# GD32H71x_72x register map
File version: 1.0
CPU: CM7 r1p2, little endian, MPU, FPU, 4 interrupt priority bits
Registers are 32-bit, read-write, reset 0x0 unless marked. A register's access mark holds for its fields unless they carry their own. Offsets are from the block's base; [hi:lo] are bit positions; {n}, {i} and the like mark numbered series; 'fields as' and 'values as' point back to an identical list.

## ADC0 — Analog-to-digital converter
Base 0x40012400
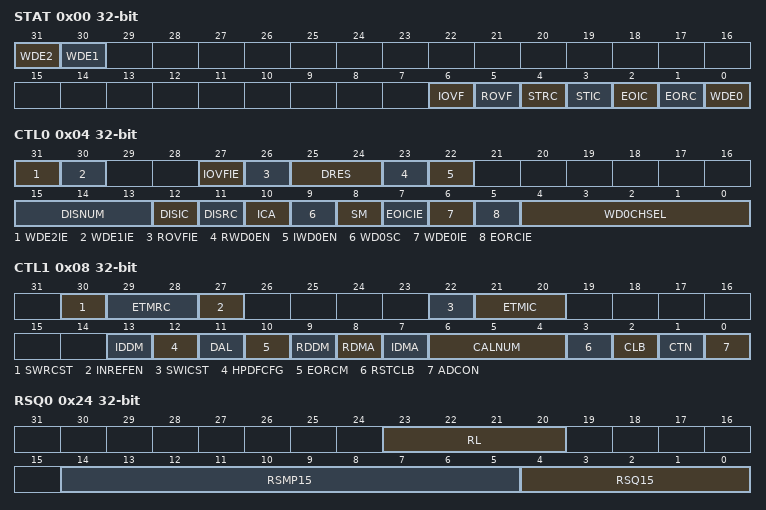
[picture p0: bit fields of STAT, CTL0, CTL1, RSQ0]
0x00 STAT — Status register
  [31] WDE2 — Analog watchdog 2 event flag
  [30] WDE1 — Analog watchdog 1 event flag
  [6] IOVF — Inserted data register overflow flag
  [5] ROVF — Routine data register overflow flag
  [4] STRC — Start flag of routine sequence
  [3] STIC — Start flag of inserted sequence
  [2] EOIC — End of inserted sequence conversion flag
  [1] EORC — End of routine sequence conversion flag
  [0] WDE0 — Analog watchdog 0 event flag
0x04 CTL0 — Control register 0
  [31] WDE2IE — Interrupt enable for WDE2
  [30] WDE1IE — Interrupt enable for WDE1
  [27] IOVFIE — Interrupt enable for IOVF
  [26] ROVFIE — Interrupt enable for ROVF
  [25:24] DRES — ADC data resolution for ADC0/ADC1
  [23] RWD0EN — Routine channel analog watchdog 0 enable
  [22] IWD0EN — Inserted channel analog watchdog 0 enable
  [15:13] DISNUM — Number of conversions in discontinuous mode
  [12] DISIC — Discontinuous mode on inserted channels
  [11] DISRC — Discontinuous mode on routine channels
  [10] ICA — Inserted sequence convert automatically
  [9] WD0SC — When in scan mode, analog watchdog 0 is effective on a single channel
  [8] SM — Scan mode
  [7] EOICIE — Interrupt enable for EOIC
  [6] WDE0IE — Interrupt enable for WDE0
  [5] EORCIE — Interrupt enable for EORC
  [4:0] WD0CHSEL — Analog watchdog 0 channel select
0x08 CTL1 — Control register 1
  [30] SWRCST — Software start on routine channel.
  [29:28] ETMRC — External trigger mode for routine channel
  [27] INREFEN — Internal reference enable
  [22] SWICST — Software start on inserted channel.
  [21:20] ETMIC — External trigger mode for inserted channel
  [13] IDDM — Inserted DMA disable mode
  [12] HPDFCFG — HPDF mode configuration
  [11] DAL — Data alignment
  [10] EORCM — End of routine sequence conversion mode
  [9] RDDM — Routine DMA disable mode
  [8] RDMA — Routine DMA request enable.
  [7] IDMA — Inserted DMA request enable.
  [6:4] CALNUM — Calibration Times
  [3] RSTCLB — Reset calibration
  [2] CLB — ADC calibration
  [1] CTN — Continuous mode
  [0] ADCON
{0xC+4i} IOFF{i} (i=0..3) — Inserted channel data offset registe {i}
  [21:0] IOFF — Data offset for inserted channel x
0x1C WDHT0 reset 0x3FFFFF — Watchdog high threshold register0
  [21:0] WDHT0 — High threshold for analog watchdog 0
0x20 WDLT0 — Watchdog low threshold register0
  [21:0] WDLT0 — Low threshold for analog watchdog 0
0x24 RSQ0 — Routine sequence register 0
  [23:20] RL — Routine channel length.
  [14:5] RSMP15 — Routine channel sample time
  [4:0] RSQ15 — refer to RSQ0[4:0] description
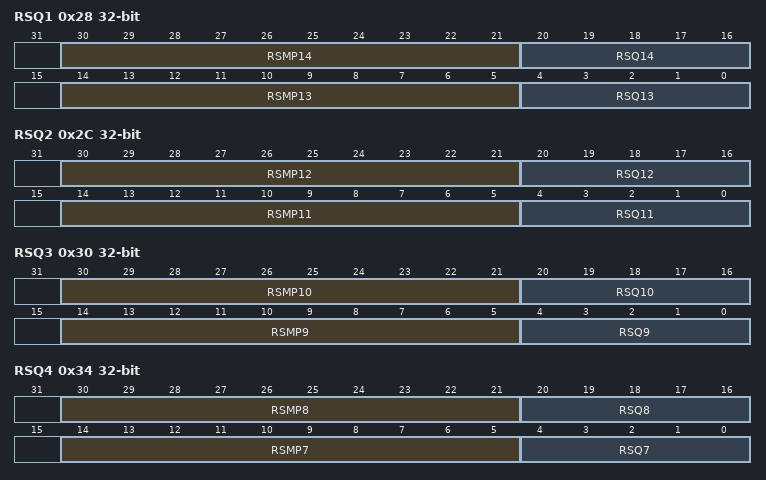
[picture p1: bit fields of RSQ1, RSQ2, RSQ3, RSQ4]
0x28 RSQ1 — Routine sequence register 1
  [30:21] RSMP14 — Routine channel sample time
  [20:16] RSQ14 — refer to RSQ0[4:0] description
  [14:5] RSMP13 — Routine channel sample time
  [4:0] RSQ13 — refer to RSQ0[4:0] description
0x2C RSQ2 — Routine sequence register 2
  [30:21] RSMP12 — Routine channel sample time
  [20:16] RSQ12 — refer to RSQ0[4:0] description
  [14:5] RSMP11 — Routine channel sample time
  [4:0] RSQ11 — refer to RSQ0[4:0] description
0x30 RSQ3 — Routine sequence register 3
  [30:21] RSMP10 — Routine channel sample time
  [20:16] RSQ10 — refer to RSQ0[4:0] description
  [14:5] RSMP9 — Routine channel sample time
  [4:0] RSQ9 — refer to RSQ0[4:0] description
0x34 RSQ4 — Routine sequence register 4
  [30:21] RSMP8 — Routine channel sample time
  [20:16] RSQ8 — refer to RSQ0[4:0] description
  [14:5] RSMP7 — Routine channel sample time
  [4:0] RSQ7 — refer to RSQ0[4:0] description
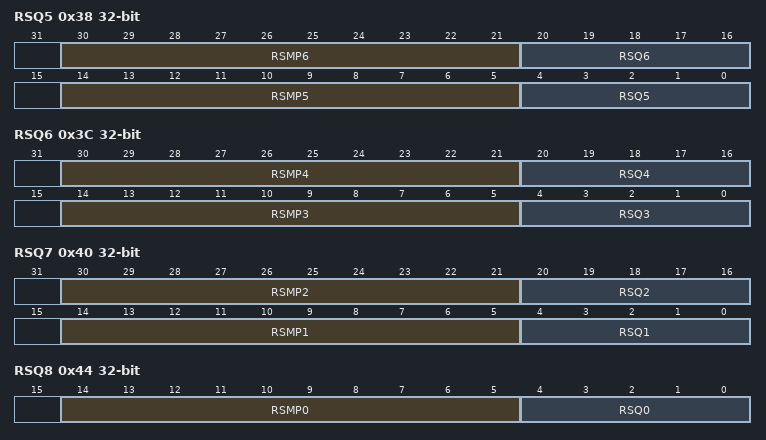
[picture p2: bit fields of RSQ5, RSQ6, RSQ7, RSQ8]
0x38 RSQ5 — Routine sequence register 5
  [30:21] RSMP6 — Routine channel sample time
  [20:16] RSQ6 — refer to RSQ0[4:0] description
  [14:5] RSMP5 — Routine channel sample time
  [4:0] RSQ5 — refer to RSQ0[4:0] description
0x3C RSQ6 — Routine sequence register 6
  [30:21] RSMP4 — Routine channel sample time
  [20:16] RSQ4 — refer to RSQ0[4:0] description
  [14:5] RSMP3 — Routine channel sample time
  [4:0] RSQ3 — refer to RSQ0[4:0] description
0x40 RSQ7 — Routine sequence register 7
  [30:21] RSMP2 — Routine channel sample time
  [20:16] RSQ2 — refer to RSQ0[4:0] description
  [14:5] RSMP1 — Routine channel sample time
  [4:0] RSQ1 — refer to RSQ0[4:0] description
0x44 RSQ8 — Routine sequence register 8
  [14:5] RSMP0 — Routine channel sample time
  [4:0] RSQ0 — The channel number (0
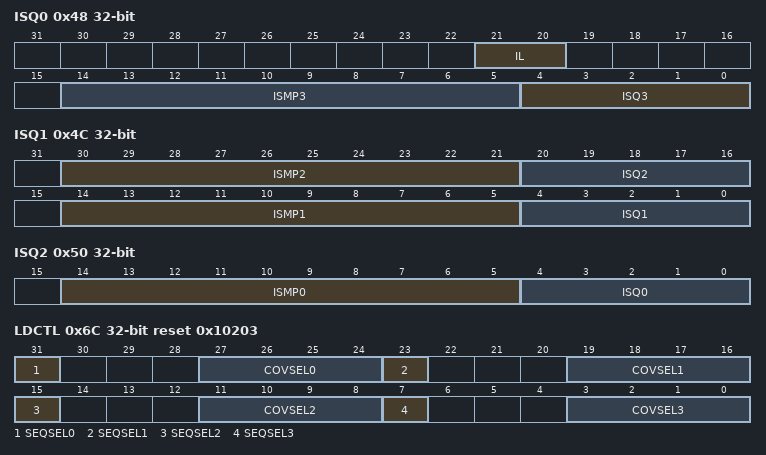
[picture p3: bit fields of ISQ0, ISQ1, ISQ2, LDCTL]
0x48 ISQ0 — Inserted sequence register 0
  [21:20] IL — Inserted sequence length.
  [14:5] ISMP3 — Inserted channel sample time
  [4:0] ISQ3 — refer to ISQ0[4:0] description
0x4C ISQ1 — Inserted sequence register 1
  [30:21] ISMP2 — Inserted channel sample time
  [20:16] ISQ2 — refer to ISQ0[4:0] description
  [14:5] ISMP1 — Inserted channel sample time
  [4:0] ISQ1 — refer to ISQ0[4:0] description.
0x50 ISQ2 — Inserted sequence register 2
  [14:5] ISMP0 — Inserted channel sample time
  [4:0] ISQ0 — The channel number (0..29) is written to these bits to select a channel at the nth conversion in the inserted sequence
0x54 LDATA0 ro — Latch data register 0
  [31:0] LDATA0 — Inserted or routine number 0 conversion data.
0x58 LDATA1 ro — Latch data register 1
  [31:0] LDATA1 — Inserted or routine number 1 conversion data.
0x5C LDATA2 ro — Latch data register 2
  [31:0] LDATA2 — Inserted number 2 conversion data
0x60 LDATA3 ro — Latch data register 3
  [31:0] LDATA3 — Inserted or routine number 3 conversion data.
0x64 RDATA ro — Routine data register
  [31:0] RDATA — Routine data.
0x68 IDATA ro — Inserted data register
  [31:0] IDATAN — Inserted data.
0x6C LDCTL reset 0x10203 — Latch data control register
  [31] SEQSEL0 — The ADC_LDATA0 register sequence source selection
  [27:24] COVSEL0 — The ADC_LDATA0 register conversion source selection
  [23] SEQSEL1 — Refer to SEQSEL0 description.
  [19:16] COVSEL1 — Refer to COVSEL0[3:0] description.
  [15] SEQSEL2 — Refer to SEQSEL0 description.
  [11:8] COVSEL2 — Refer to COVSEL0[3:0] description.
  [7] SEQSEL3 — Refer to SEQSEL0 description.
  [3:0] COVSEL3 — Refer to COVSEL0[3:0] description.
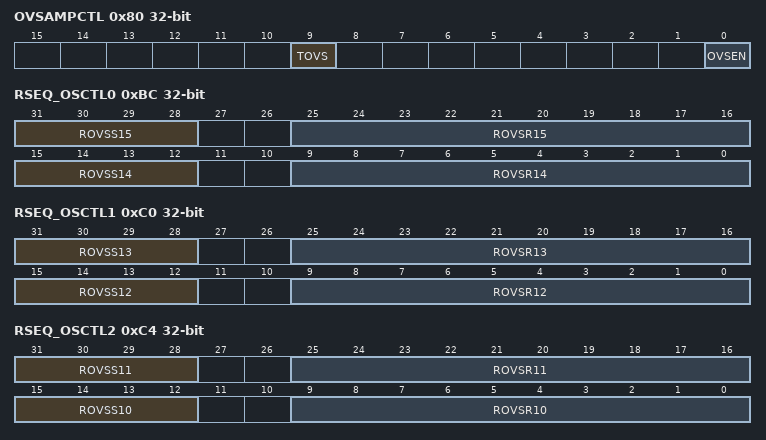
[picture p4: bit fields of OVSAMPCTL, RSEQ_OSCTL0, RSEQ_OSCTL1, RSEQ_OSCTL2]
0x80 OVSAMPCTL — Oversample control register
  [9] TOVS — Triggered Oversampling
  [0] OVSEN — Oversampler Enable
0xA0 WD1SR — Watchdog 1 Channel Selection Register
  [29:0] AWD1CS — Analog watchdog 1 channel selection
0xA4 WD2SR — Watchdog 2 Channel Selection Register
  [29:0] AWD2CS — Analog watchdog 2 channel selection
0xA8 WDHT1 reset 0x3FFFFF — Watchdog high threshold register1
  [21:0] WDHT1 — High threshold for analog watchdog 1
0xAC WDLT1 — Watchdog low threshold register1
  [21:0] WDLT1 — Low threshold for analog watchdog 1
0xB0 WDHT2 reset 0x3FFFFF — Watchdog high threshold register2
  [21:0] WDHT2 — High threshold for analog watchdog 2
0xB4 WDLT2 — Watchdog low threshold register2
  [21:0] WDLT2 — Low threshold for analog watchdog 2
0xB8 DIFCTL — Differential mode control register
  [29:0] DIFCTL — Differential mode for channel 21..0.
0xBC RSEQ_OSCTL0 — Routine sequence oversample control register 0
  [31:28] ROVSS15 — Oversampling shift of routine sequence 15
  [25:16] ROVSR15 — The Oversampling ratio of routine sequence 15
  [15:12] ROVSS14 — Oversampling shift of routine sequence 14
  [9:0] ROVSR14 — The Oversampling ratio of routine sequence 14
0xC0 RSEQ_OSCTL1 — Routine sequence oversample control register 1
  [31:28] ROVSS13 — Oversampling shift of routine sequence 13
  [25:16] ROVSR13 — The Oversampling ratio of routine sequence 13
  [15:12] ROVSS12 — Oversampling shift of routine sequence 12
  [9:0] ROVSR12 — The Oversampling ratio of routine sequence 12
0xC4 RSEQ_OSCTL2 — Routine sequence oversample control register 2
  [31:28] ROVSS11 — Oversampling shift of Routine sequence 11
  [25:16] ROVSR11 — The Oversampling ratio of routine sequence 11
  [15:12] ROVSS10 — Oversampling shift of routine sequence 10
  [9:0] ROVSR10 — The Oversampling ratio of routine sequence 10
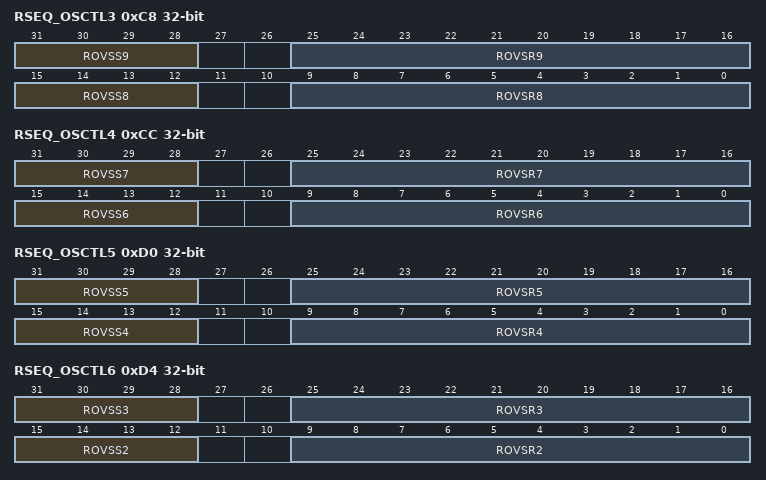
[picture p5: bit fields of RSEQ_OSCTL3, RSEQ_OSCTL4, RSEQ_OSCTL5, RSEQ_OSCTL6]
0xC8 RSEQ_OSCTL3 — Routine sequence oversample control register 3
  [31:28] ROVSS9 — Oversampling shift of routine sequence 9
  [25:16] ROVSR9 — The Oversampling ratio of routine sequence 9
  [15:12] ROVSS8 — Oversampling shift of routine sequence 8
  [9:0] ROVSR8 — The Oversampling ratio of routine sequence 8
0xCC RSEQ_OSCTL4 — Routine sequence oversample control register 4
  [31:28] ROVSS7 — Oversampling shift of routine sequence 7
  [25:16] ROVSR7 — The Oversampling ratio of routine sequence 7
  [15:12] ROVSS6 — Oversampling shift of routine sequence 6
  [9:0] ROVSR6 — The Oversampling ratio of routine sequence 6
0xD0 RSEQ_OSCTL5 — Routine sequence oversample control register 5
  [31:28] ROVSS5 — Oversampling shift of routine sequence 5
  [25:16] ROVSR5 — The Oversampling ratio of routine sequence 5
  [15:12] ROVSS4 — Oversampling shift of routine sequence 4
  [9:0] ROVSR4 — The Oversampling ratio of routine sequence 4
0xD4 RSEQ_OSCTL6 — Routine sequence oversample control register 6
  [31:28] ROVSS3 — Oversampling shift of routine sequence 3
  [25:16] ROVSR3 — The Oversampling ratio of routine sequence 3
  [15:12] ROVSS2 — Oversampling shift of routine sequence 2
  [9:0] ROVSR2 — The Oversampling ratio of routine sequence 2
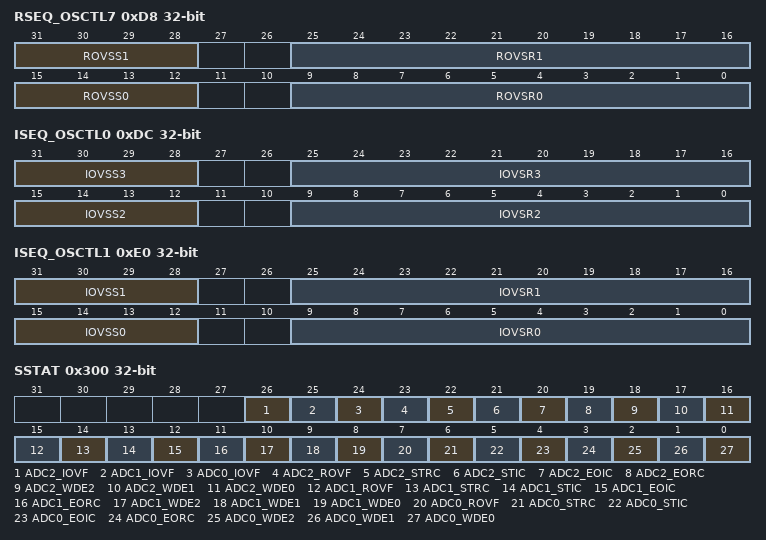
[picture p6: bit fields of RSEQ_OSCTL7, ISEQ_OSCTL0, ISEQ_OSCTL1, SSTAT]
0xD8 RSEQ_OSCTL7 — Routine sequence oversample control register 7
  [31:28] ROVSS1 — Oversampling shift of routine sequence 1
  [25:16] ROVSR1 — The Oversampling ratio of routine sequence 1
  [15:12] ROVSS0 — Oversampling shift of routine sequence 0
  [9:0] ROVSR0 — The Oversampling ratio of routine sequence 0.
0xDC ISEQ_OSCTL0 — Inserted sequence oversample control register 0
  [31:28] IOVSS3 — Oversampling shift of Inserted Sequence 3
  [25:16] IOVSR3 — The Oversampling ratio of Inserted Sequence 3
  [15:12] IOVSS2 — Oversampling shift of Inserted Sequence 2
  [9:0] IOVSR2 — The Oversampling ratio of Inserted Sequence 2
0xE0 ISEQ_OSCTL1 — Inserted sequence oversample control register 1
  [31:28] IOVSS1 — Oversampling shift of Inserted Sequence 1
  [25:16] IOVSR1 — The Oversampling ratio of Inserted Sequence 1
  [15:12] IOVSS0 — Oversampling shift of Inserted Sequence 0
  [9:0] IOVSR0 — The Oversampling ratio of Inserted Sequence 0
0x300 SSTAT ro — Summary status register
  [26] ADC2_IOVF — This bit is the mirror image of the IOVF bit of ADC2
  [25] ADC1_IOVF — This bit is the mirror image of the IOVF bit of ADC1
  [24] ADC0_IOVF — This bit is the mirror image of the IOVF bit of ADC0
  [23] ADC2_ROVF — This bit is the mirror image of the ROVF bit of ADC2
  [22] ADC2_STRC — This bit is the mirror image of the STRC bit of ADC2
  [21] ADC2_STIC — This bit is the mirror image of the STIC bit of ADC2
  [20] ADC2_EOIC — This bit is the mirror image of the EOIC bit of ADC2
  [19] ADC2_EORC — This bit is the mirror image of the EORC bit of ADC2
  [18] ADC2_WDE2 — This bit is the mirror image of the WDE2 bit of ADC2
  [17] ADC2_WDE1 — This bit is the mirror image of the WDE1 bit of ADC2
  [16] ADC2_WDE0 — This bit is the mirror image of the WDE0 bit of ADC2
  [15] ADC1_ROVF — This bit is the mirror image of the ROVF bit of ADC1
  [14] ADC1_STRC — This bit is the mirror image of the STRC bit of ADC1
  [13] ADC1_STIC — This bit is the mirror image of the STIC bit of ADC1
  [12] ADC1_EOIC — This bit is the mirror image of the EOIC bit of ADC1
  [11] ADC1_EORC — This bit is the mirror image of the EORC bit of ADC1
  [10] ADC1_WDE2 — This bit is the mirror image of the WDE2 bit of ADC1
  [9] ADC1_WDE1 — This bit is the mirror image of the WDE1 bit of ADC1
  [8] ADC1_WDE0 — This bit is the mirror image of the WDE0 bit of ADC1
  [7] ADC0_ROVF — This bit is the mirror image of the ROVF bit of ADC0
  [6] ADC0_STRC — This bit is the mirror image of the STRC bit of ADC0
  [5] ADC0_STIC — This bit is the mirror image of the STIC bit of ADC0
  [4] ADC0_EOIC — This bit is the mirror image of the EOIC bit of ADC0
  [3] ADC0_EORC — This bit is the mirror image of the EORC bit of ADC0
  [2] ADC0_WDE2 — This bit is the mirror image of the WDE2 bit of ADC0
  [1] ADC0_WDE1 — This bit is the mirror image of the WDE1 bit of ADC0
  [0] ADC0_WDE0 — This bit is the mirror image of the WDE0 bit of ADC0
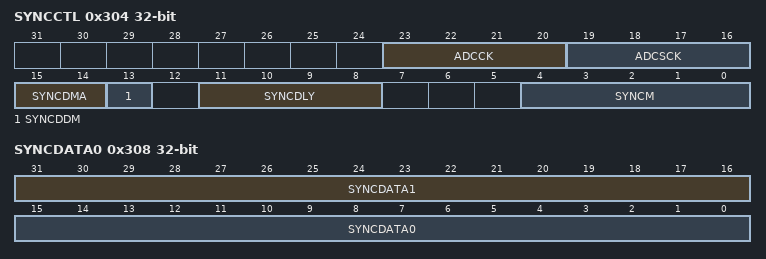
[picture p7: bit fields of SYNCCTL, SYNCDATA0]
0x304 SYNCCTL — Sync control register
  [23:20] ADCCK — ADC clock prescaler.
  [19:16] ADCSCK — ADC sync clock mode
  [15:14] SYNCDMA — ADC sync DMA mode selection
  [13] SYNCDDM — ADC sync DMA disable mode
  [11:8] SYNCDLY — ADC sync delay
  [4:0] SYNCM — ADC sync mode
0x308 SYNCDATA0 ro — Sync routine data register0
  [31:16] SYNCDATA1 — Routine data1(slave adc routine data) in ADC sync mode..
  [15:0] SYNCDATA0 — Routine data0 (master adc routine data) in ADC sync mode.
0x30C SYNCDATA1 ro — Sync routine data register1
  [31:0] SYNCDATA — SYNCDMA[1:0]=2b01, which is selected from the routine data (master,slave) of the ADCs in turn

## ADC1 — Analog-to-digital converter
Base 0x40012800
Registers as ADC0, without LDCTL, SSTAT, SYNCCTL, SYNCDATA0, SYNCDATA1; these are added or differ:
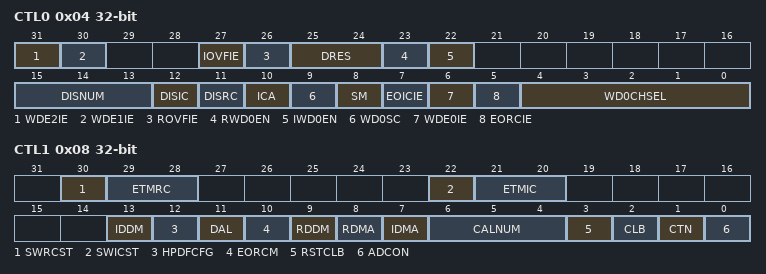
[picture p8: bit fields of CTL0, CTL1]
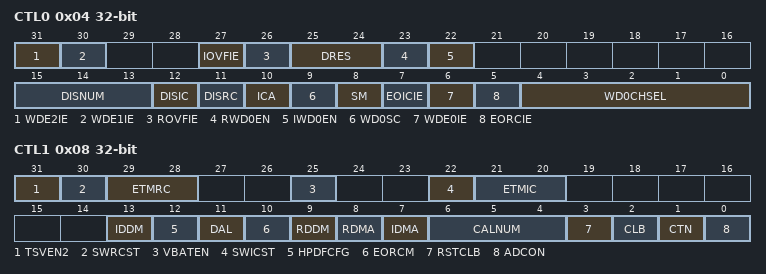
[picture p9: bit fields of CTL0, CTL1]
0x04 CTL0 — Control register 0
  fields as ADC0.CTL0
0x08 CTL1 — Control register 1
  [30] SWRCST — Software start on routine channel.
  [29:28] ETMRC — External trigger mode for routine channel
  [22] SWICST — Software start on inserted channel.
  [21:20] ETMIC — External trigger mode for inserted channel
  [13] IDDM — Inserted DMA disable mode
  [12] HPDFCFG — HPDF mode configuration
  [11] DAL — Data alignment
  [10] EORCM — End of routine sequence conversion mode
  [9] RDDM — Routine DMA disable mode
  [8] RDMA — Routine DMA request enable.
  [7] IDMA — Inserted DMA request enable.
  [6:4] CALNUM — Calibration Times
  [3] RSTCLB — Reset calibration
  [2] CLB — ADC calibration
  [1] CTN — Continuous mode
  [0] ADCON

## ADC2 — Analog-to-digital converter
Base 0x40012C00
Registers as ADC0, without LDCTL, SSTAT, SYNCCTL, SYNCDATA0, SYNCDATA1; these are added or differ:
0x04 CTL0 — Control register 0
  fields as ADC0.CTL0
0x08 CTL1 — Control register 1
  [31] TSVEN2 — Temperature sensor enable
  [30] SWRCST — Software start on routine channel.
  [29:28] ETMRC — External trigger mode for routine channel
  [25] VBATEN — VBAT enable
  [22] SWICST — Software start on inserted channel.
  [21:20] ETMIC — External trigger mode for inserted channel
  [13] IDDM — Inserted DMA disable mode
  [12] HPDFCFG — HPDF mode configuration
  [11] DAL — Data alignment
  [10] EORCM — End of routine sequence conversion mode
  [9] RDDM — Routine DMA disable mode
  [8] RDMA — Routine DMA request enable.
  [7] IDMA — Inserted DMA request enable.
  [6:4] CALNUM — Calibration Times
  [3] RSTCLB — Reset calibration
  [2] CLB — ADC calibration
  [1] CTN — Continuous mode
  [0] ADCON
